VERSION ""
NS_ :

BS_:

BU_: DCM FSM JCT

BO_ 200 DcmVitals: 1 DCM
SG_ Heartbeat : 0|1@1+ (1,0) [0|1] "" DEBUG

BO_ 201 DcmCanFifoOverflow: 8 DCM
SG_ TxOverflowCount : 0|32@1+ (1,0) [0|4294967295] "" DEBUG
SG_ RxOverflowCount : 32|32@1+ (1,0) [0|4294967295] "" DEBUG

BO_ 203 DcmWatchdogTimeout: 4 DCM
SG_ TaskName : 0|32@1+ (1,0) [0|4294967295] "" DEBUG

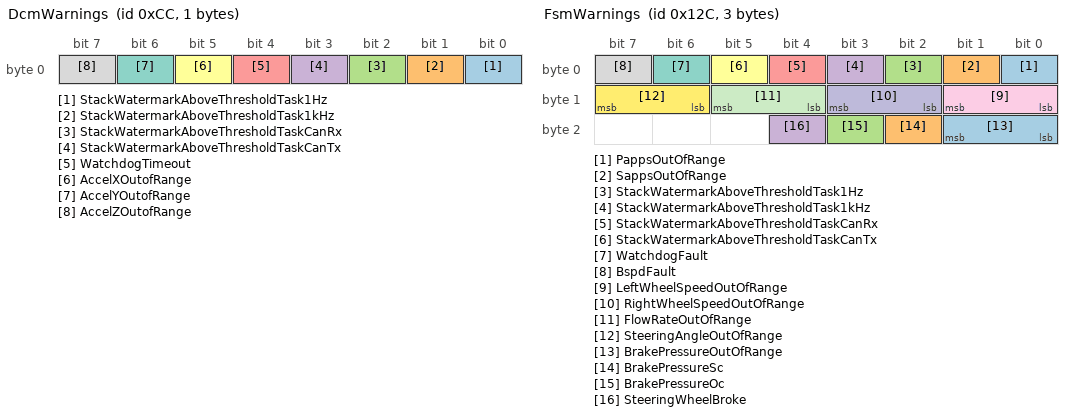
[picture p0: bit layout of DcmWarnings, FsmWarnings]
BO_ 204 DcmWarnings: 1 DCM
SG_ StackWatermarkAboveThresholdTask1Hz : 0|1@1+ (1,0) [0|1] "" DEBUG
SG_ StackWatermarkAboveThresholdTask1kHz : 1|1@1+ (1,0) [0|1] "" DEBUG
SG_ StackWatermarkAboveThresholdTaskCanRx : 2|1@1+ (1,0) [0|1] "" DEBUG
SG_ StackWatermarkAboveThresholdTaskCanTx : 3|1@1+ (1,0) [0|1] "" DEBUG
SG_ WatchdogTimeout : 4|1@1+ (1,0) [0|1] "" DEBUG
SG_ AccelXOutofRange : 5|1@1+ (1,0) [0|1] "" DEBUG
SG_ AccelYOutofRange : 6|1@1+ (1,0) [0|1] "" DEBUG
SG_ AccelZOutofRange : 7|1@1+ (1,0) [0|1] "" DEBUG

BO_ 205 DcmStateMachine: 1 DCM
SG_ State : 0|8@1+ (1,0) [0|255] "" DEBUG

BO_ 207 DcmAirShutdownErrors: 1 DCM
SG_ MissingHeartbeat : 0|1@1+ (1,0) [0|1] "" DEBUG

BO_ 208 DcmMotorShutdownErrors: 1 DCM
SG_ MissingHeartbeat : 0|1@1+ (1,0) [0|1] "" DEBUG

BO_ 212 DcmInverterSwitches: 1 DCM
SG_ RightInverterSwitch : 0|1@1+ (1,0) [0|1] "" DEBUG
SG_ LeftInverterSwitch : 1|1@1+ (1,0) [0|1] "" DEBUG

BO_ 13 FsmPedalPosition: 4 FSM
SG_ MappedPedalPercentage : 0|32@1+ (2.3283064370807974e-08,0) [0|100] "%" DEBUG

BO_ 90 FsmTorqueLimiting: 4 FSM
SG_ FsmTorqueLimit : 0|32@1+ (3.492459655621196e-08,0) [0|150] "nM" DEBUG

BO_ 151 FsmApps: 8 FSM
SG_ PappsMappedPedalPercentage : 0|32@1+ (2.3283064370807974e-08,0) [0|100] "%" DEBUG,JCT
SG_ SappsMappedPedalPercentage : 32|32@1+ (2.3283064370807974e-08,0) [0|100] "%" DEBUG,JCT

BO_ 300 FsmWarnings: 3 FSM
SG_ PappsOutOfRange : 0|1@1+ (1,0) [0|1] "" DEBUG,JCT
SG_ SappsOutOfRange : 1|1@1+ (1,0) [0|1] "" DEBUG,JCT
SG_ StackWatermarkAboveThresholdTask1Hz : 2|1@1+ (1,0) [0|1] "" DEBUG,JCT
SG_ StackWatermarkAboveThresholdTask1kHz : 3|1@1+ (1,0) [0|1] "" DEBUG,JCT
SG_ StackWatermarkAboveThresholdTaskCanRx : 4|1@1+ (1,0) [0|1] "" DEBUG,JCT
SG_ StackWatermarkAboveThresholdTaskCanTx : 5|1@1+ (1,0) [0|1] "" DEBUG,JCT
SG_ WatchdogFault : 6|1@1+ (1,0) [0|1] "" DEBUG,JCT
SG_ BspdFault : 7|1@1+ (1,0) [0|1] "" DEBUG,JCT
SG_ LeftWheelSpeedOutOfRange : 8|2@1+ (1,0) [0|3] "" DEBUG,JCT
SG_ RightWheelSpeedOutOfRange : 10|2@1+ (1,0) [0|3] "" DEBUG,JCT
SG_ FlowRateOutOfRange : 12|2@1+ (1,0) [0|3] "" DEBUG,JCT
SG_ SteeringAngleOutOfRange : 14|2@1+ (1,0) [0|3] "" DEBUG,JCT
SG_ BrakePressureOutOfRange : 16|2@1+ (1,0) [0|3] "" DEBUG,JCT
SG_ BrakePressureSc : 18|1@1+ (1,0) [0|1] "" DEBUG,JCT
SG_ BrakePressureOc : 19|1@1+ (1,0) [0|1] "" DEBUG,JCT
SG_ SteeringWheelBroke : 20|1@1+ (1,0) [0|1] "" DEBUG,JCT

BO_ 301 FsmVitals: 1 FSM
SG_ Heartbeat : 0|1@1+ (1,0) [0|1] "" DEBUG

BO_ 302 FsmCanFifoOverflow: 8 FSM
SG_ TxOverflowCount : 0|32@1+ (1,0) [0|4294967295] "" DEBUG
SG_ RxOverflowCount : 32|32@1+ (1,0) [0|4294967295] "" DEBUG

BO_ 304 WatchdogTimeout: 1 FSM
SG_ TaskName : 0|8@1+ (1,0) [0|255] "" DEBUG

BO_ 305 FsmStateMachine: 1 FSM
SG_ State : 0|8@1+ (1,0) [0|255] "" DEBUG

BO_ 307 FsmFlowMeter: 1 FSM
SG_ FlowRate : 0|8@1+ (0.39215686274509803,0) [0|100] "L/min" DEBUG

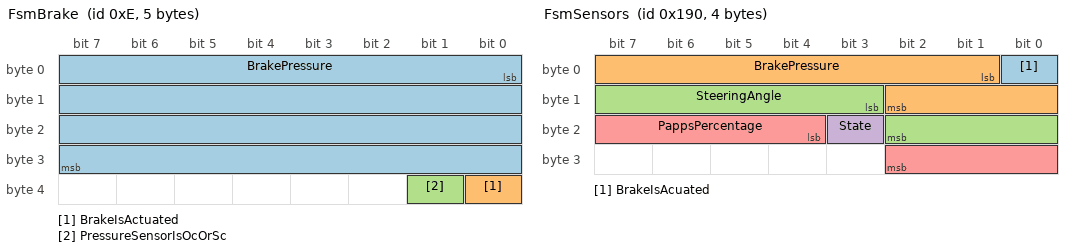
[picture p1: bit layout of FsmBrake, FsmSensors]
BO_ 14 FsmBrake: 5 FSM
SG_ BrakePressure : 0|32@1+ (5.820766092701993e-07,0) [0|2500] "psi" DEBUG
SG_ BrakeIsActuated : 32|1@1+ (1,0) [0|1] "" DEBUG
SG_ PressureSensorIsOcOrSc : 33|1@1+ (1,0) [0|1] "" DEBUG

BO_ 400 FsmSensors: 4 FSM
SG_ BrakeIsAcuated : 0|1@1+ (1,0) [0|1] "" DEBUG
SG_ BrakePressure : 1|10@1+ (2.4437927663734116,0) [0|2500] "psi" DEBUG
SG_ SteeringAngle : 11|8@1+ (1,-120) [-120|120] "" DEBUG
SG_ State : 19|1@1+ (1,0) [0|1] "" DEBUG
SG_ PappsPercentage : 20|7@1- (1,0) [0|100] "%" DEBUG

BO_ 310 FsmAirShutdownErrors: 1 FSM
SG_ MissingHeartbeat : 0|1@1+ (1,0) [0|1] "" DEBUG

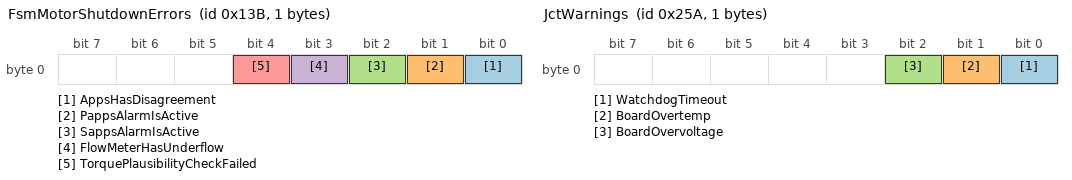
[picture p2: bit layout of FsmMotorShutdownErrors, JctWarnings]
BO_ 315 FsmMotorShutdownErrors: 1 FSM
SG_ AppsHasDisagreement : 0|1@1+ (1,0) [0|1] "" DEBUG
SG_ PappsAlarmIsActive : 1|1@1+ (1,0) [0|1] "" DEBUG
SG_ SappsAlarmIsActive : 2|1@1+ (1,0) [0|1] "" DEBUG
SG_ FlowMeterHasUnderflow : 3|1@1+ (1,0) [0|1] "" DEBUG
SG_ TorquePlausibilityCheckFailed : 4|1@1+ (1,0) [0|1] "" DEBUG

BO_ 317 FsmWheelSpeedSensors: 4 FSM
SG_ LeftWheelSpeed : 0|16@1+ (0.0022888532845044634,0) [0|150] "km/h" DEBUG
SG_ RightWheelSpeed : 32|16@1+ (0.0022888532845044634,0) [0|150] "km/h" DEBUG

BO_ 318 FsmSteeringAngleSensor: 4 FSM
SG_ SteeringAngle : 0|32@1+ (5.122274161577754e-08,-110) [-110|110] "km/h" DEBUG

BO_ 42 FSM_AlertSet: 1 FSM
SG_ FSM_AlertSet : 0|1@1+ (1,0) [0|1] "" DEBUG

BO_ 43 FSM_AlertCleared: 1 FSM
SG_ FSM_AlertCleared : 0|1@1+ (1,0) [0|1] "" DEBUG

BO_ 601 JctVitals: 5 JCT
SG_ Heartbeat : 0|1@1+ (1.0,0) [0|1] "" DEBUG
SG_ Timestamp : 1|32@1+ (1,0) [0|4294967295] "" DEBUG

BO_ 602 JctWarnings: 1 JCT
SG_ WatchdogTimeout : 0|1@1+ (1,0) [0|1] "" DEBUG
SG_ BoardOvertemp : 1|1@1+ (1,0) [0|1] "" DEBUG
SG_ BoardOvervoltage : 2|1@1+ (1,0) [0|1] "" DEBUG

BO_ 603 JctAirShutdownErrors: 1 JCT
SG_ DummyAirShutdown : 0|1@1+ (1,0) [0|1] "" DEBUG

BO_ 604 JctMotorShutdownErrors: 1 JCT
SG_ DummyMotorShutdown : 0|1@1+ (1,0) [0|1] "" DEBUG

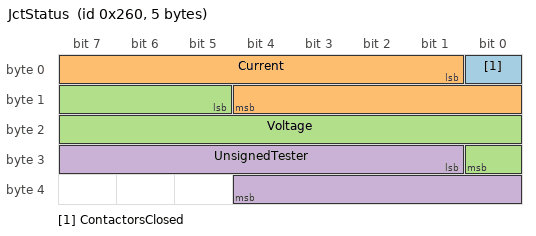
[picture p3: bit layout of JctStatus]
BO_ 608 JctStatus: 5 JCT
SG_ ContactorsClosed : 0|1@1+ (1,0) [0|1] "" DEBUG
SG_ Current : 1|12@1+ (0.02442002442002442,0) [0|100] "A" DEBUG
SG_ Voltage : 13|12@1+ (0.1221001221001221,0) [0|500] "V" DEBUG
SG_ UnsignedTester : 25|12@1- (1,0) [-2047|2046] "V" DEBUG

BO_ 40 JCT_AlertSet: 1 JCT
SG_ JCT_AlertSet : 0|3@1+ (1,0) [0|7] "" DEBUG

BO_ 41 JCT_AlertCleared: 1 JCT
SG_ JCT_AlertCleared : 0|3@1+ (1,0) [0|7] "" DEBUG

BA_DEF_  "BusType" STRING ;
BA_DEF_DEF_  "BusType" "CAN";

BA_ "GenSigStartValue" SG_ 200 Heartbeat 0;
BA_ "GenSigStartValue" SG_ 201 TxOverflowCount 0;
BA_ "GenSigStartValue" SG_ 201 RxOverflowCount 0;
BA_ "GenSigStartValue" SG_ 203 TaskName 0;
BA_ "GenSigStartValue" SG_ 204 StackWatermarkAboveThresholdTask1Hz 0;
BA_ "GenSigStartValue" SG_ 204 StackWatermarkAboveThresholdTask1kHz 0;
BA_ "GenSigStartValue" SG_ 204 StackWatermarkAboveThresholdTaskCanRx 0;
BA_ "GenSigStartValue" SG_ 204 StackWatermarkAboveThresholdTaskCanTx 0;
BA_ "GenSigStartValue" SG_ 204 WatchdogTimeout 0;
BA_ "GenSigStartValue" SG_ 204 AccelXOutofRange 0;
BA_ "GenSigStartValue" SG_ 204 AccelYOutofRange 0;
BA_ "GenSigStartValue" SG_ 204 AccelZOutofRange 0;
BA_ "GenSigStartValue" SG_ 205 State 0;
BA_ "GenSigStartValue" SG_ 207 MissingHeartbeat 0;
BA_ "GenSigStartValue" SG_ 208 MissingHeartbeat 0;
BA_ "GenSigStartValue" SG_ 212 RightInverterSwitch 0;
BA_ "GenSigStartValue" SG_ 212 LeftInverterSwitch 0;
BA_ "GenSigStartValue" SG_ 13 MappedPedalPercentage 0;
BA_ "GenSigStartValue" SG_ 90 FsmTorqueLimit 0;
BA_ "GenSigStartValue" SG_ 151 PappsMappedPedalPercentage 0;
BA_ "GenSigStartValue" SG_ 151 SappsMappedPedalPercentage 0;
BA_ "GenSigStartValue" SG_ 300 PappsOutOfRange 0;
BA_ "GenSigStartValue" SG_ 300 SappsOutOfRange 0;
BA_ "GenSigStartValue" SG_ 300 StackWatermarkAboveThresholdTask1Hz 0;
BA_ "GenSigStartValue" SG_ 300 StackWatermarkAboveThresholdTask1kHz 0;
BA_ "GenSigStartValue" SG_ 300 StackWatermarkAboveThresholdTaskCanRx 0;
BA_ "GenSigStartValue" SG_ 300 StackWatermarkAboveThresholdTaskCanTx 0;
BA_ "GenSigStartValue" SG_ 300 WatchdogFault 0;
BA_ "GenSigStartValue" SG_ 300 BspdFault 0;
BA_ "GenSigStartValue" SG_ 300 LeftWheelSpeedOutOfRange 0;
BA_ "GenSigStartValue" SG_ 300 RightWheelSpeedOutOfRange 0;
BA_ "GenSigStartValue" SG_ 300 FlowRateOutOfRange 0;
BA_ "GenSigStartValue" SG_ 300 SteeringAngleOutOfRange 0;
BA_ "GenSigStartValue" SG_ 300 BrakePressureOutOfRange 0;
BA_ "GenSigStartValue" SG_ 300 BrakePressureSc 0;
BA_ "GenSigStartValue" SG_ 300 BrakePressureOc 0;
BA_ "GenSigStartValue" SG_ 300 SteeringWheelBroke 0;
BA_ "GenSigStartValue" SG_ 301 Heartbeat 0;
BA_ "GenSigStartValue" SG_ 302 TxOverflowCount 0;
BA_ "GenSigStartValue" SG_ 302 RxOverflowCount 0;
BA_ "GenSigStartValue" SG_ 304 TaskName 0;
BA_ "GenSigStartValue" SG_ 305 State 0;
BA_ "GenSigStartValue" SG_ 307 FlowRate 0;
BA_ "GenSigStartValue" SG_ 14 BrakePressure 0;
BA_ "GenSigStartValue" SG_ 14 BrakeIsActuated 0;
BA_ "GenSigStartValue" SG_ 14 PressureSensorIsOcOrSc 0;
BA_ "GenSigStartValue" SG_ 400 BrakeIsAcuated 0;
BA_ "GenSigStartValue" SG_ 400 BrakePressure 0;
BA_ "GenSigStartValue" SG_ 400 SteeringAngle -120;
BA_ "GenSigStartValue" SG_ 400 State 0;
BA_ "GenSigStartValue" SG_ 400 PappsPercentage 0;
BA_ "GenSigStartValue" SG_ 310 MissingHeartbeat 0;
BA_ "GenSigStartValue" SG_ 315 AppsHasDisagreement 0;
BA_ "GenSigStartValue" SG_ 315 PappsAlarmIsActive 0;
BA_ "GenSigStartValue" SG_ 315 SappsAlarmIsActive 0;
BA_ "GenSigStartValue" SG_ 315 FlowMeterHasUnderflow 0;
BA_ "GenSigStartValue" SG_ 315 TorquePlausibilityCheckFailed 0;
BA_ "GenSigStartValue" SG_ 317 LeftWheelSpeed 0;
BA_ "GenSigStartValue" SG_ 317 RightWheelSpeed 0;
BA_ "GenSigStartValue" SG_ 318 SteeringAngle -110;
BA_ "GenSigStartValue" SG_ 42 FSM_AlertSet 0;
BA_ "GenSigStartValue" SG_ 43 FSM_AlertCleared 0;
BA_ "GenSigStartValue" SG_ 601 Heartbeat 0;
BA_ "GenSigStartValue" SG_ 601 Timestamp 0;
BA_ "GenSigStartValue" SG_ 602 WatchdogTimeout 0;
BA_ "GenSigStartValue" SG_ 602 BoardOvertemp 0;
BA_ "GenSigStartValue" SG_ 602 BoardOvervoltage 0;
BA_ "GenSigStartValue" SG_ 603 DummyAirShutdown 0;
BA_ "GenSigStartValue" SG_ 604 DummyMotorShutdown 0;
BA_ "GenSigStartValue" SG_ 608 ContactorsClosed 0;
BA_ "GenSigStartValue" SG_ 608 Current 50;
BA_ "GenSigStartValue" SG_ 608 Voltage 0;
BA_ "GenSigStartValue" SG_ 608 UnsignedTester -2047;
BA_ "GenSigStartValue" SG_ 40 JCT_AlertSet 0;
BA_ "GenSigStartValue" SG_ 41 JCT_AlertCleared 0;

BA_ "GenMsgCycleTime" BO_ 200  1000;
BA_ "GenMsgCycleTime" BO_ 201  1000;
BA_ "GenMsgCycleTime" BO_ 203  1000;
BA_ "GenMsgCycleTime" BO_ 204  1000;
BA_ "GenMsgCycleTime" BO_ 205  1000;
BA_ "GenMsgCycleTime" BO_ 207  1000;
BA_ "GenMsgCycleTime" BO_ 208  1000;
BA_ "GenMsgCycleTime" BO_ 212  1000;
BA_ "GenMsgCycleTime" BO_ 13  1000;
BA_ "GenMsgCycleTime" BO_ 90  1000;
BA_ "GenMsgCycleTime" BO_ 151  1000;
BA_ "GenMsgCycleTime" BO_ 300  100;
BA_ "GenMsgCycleTime" BO_ 301  1000;
BA_ "GenMsgCycleTime" BO_ 302  1000;
BA_ "GenMsgCycleTime" BO_ 304  1000;
BA_ "GenMsgCycleTime" BO_ 305  1000;
BA_ "GenMsgCycleTime" BO_ 307  1000;
BA_ "GenMsgCycleTime" BO_ 14  1000;
BA_ "GenMsgCycleTime" BO_ 400  1000;
BA_ "GenMsgCycleTime" BO_ 310  1000;
BA_ "GenMsgCycleTime" BO_ 315  1000;
BA_ "GenMsgCycleTime" BO_ 317  1000;
BA_ "GenMsgCycleTime" BO_ 318  1000;
BA_ "GenMsgCycleTime" BO_ 601  1000;
BA_ "GenMsgCycleTime" BO_ 603  1000;
BA_ "GenMsgCycleTime" BO_ 604  1000;
BA_ "GenMsgCycleTime" BO_ 608  1000;

VAL_ 200 Heartbeat 0 "FALSE" 1 "TRUE";
VAL_ 301 Heartbeat 0 "FALSE" 1 "TRUE";
VAL_ 400 State 0 "STATE_IDLE" 1 "STATE_DRIVE";
VAL_ 42 FSM_AlertSet 0 "FSM_BSPD" 1 "NUM_FSM_ALERTS";
VAL_ 43 FSM_AlertCleared 0 "FSM_BSPD" 1 "NUM_FSM_ALERTS";
VAL_ 608 ContactorsClosed 0 "AIR_OPEN" 1 "AIR_CLOSED";
VAL_ 40 JCT_AlertSet 0 "JCT_OVERTEMP" 1 "JCT_UNDERTEMP" 2 "JCT_GO_TO_INIT" 3 "NUM_JCT_ALERTS";
VAL_ 41 JCT_AlertCleared 0 "JCT_OVERTEMP" 1 "JCT_UNDERTEMP" 2 "JCT_GO_TO_INIT" 3 "NUM_JCT_ALERTS";
